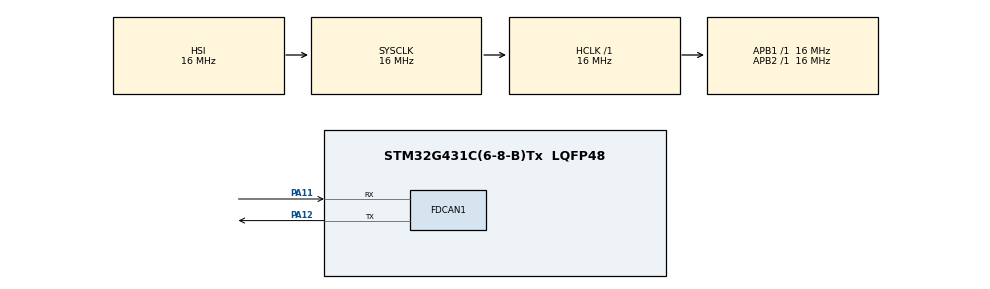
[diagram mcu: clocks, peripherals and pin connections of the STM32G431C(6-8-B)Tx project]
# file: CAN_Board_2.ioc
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FDCAN1.AutoRetransmission=DISABLE
FDCAN1.CalculateBaudRateNominal=500000
FDCAN1.CalculateTimeBitNominal=2000
FDCAN1.CalculateTimeQuantumNominal=62.5
FDCAN1.DataSyncJumpWidth=15
FDCAN1.DataTimeSeg1=16
FDCAN1.DataTimeSeg2=15
FDCAN1.FrameFormat=FDCAN_FRAME_FD_NO_BRS
FDCAN1.NominalPrescaler=1
FDCAN1.NominalSyncJumpWidth=2
FDCAN1.NominalTimeSeg1=29
Mcu.Family=STM32G4
Mcu.Name=STM32G431C(6-8-B)Tx
Mcu.Package=LQFP48
NVIC.FDCAN1_IT0_IRQn=true\:0\:0\:false\:false\:true\:true\:true\:true
NVIC.PriorityGroup=NVIC_PRIORITYGROUP_4
PA11.Mode=FDCAN_Activate
PA11.Signal=FDCAN1_RX
PA12.Mode=FDCAN_Activate
PA12.Signal=FDCAN1_TX
ProjectManager.HeapSize=0x200
ProjectManager.StackSize=0x400
ProjectManager.TargetToolchain=STM32CubeIDE
RCC.AHBFreq_Value=16000000
RCC.APB1Freq_Value=16000000
RCC.APB1TimFreq_Value=16000000
RCC.APB2Freq_Value=16000000
RCC.APB2TimFreq_Value=16000000
RCC.CortexFreq_Value=16000000
RCC.EXTERNAL_CLOCK_VALUE=12288000
RCC.HCLKFreq_Value=16000000
RCC.HSE_VALUE=8000000
RCC.HSI48_VALUE=48000000
RCC.HSI_VALUE=16000000
RCC.LSE_VALUE=32768
RCC.SYSCLKFreq_VALUE=16000000
RCC.USBFreq_Value=64000000
RCC.VCOOutputFreq_Value=128000000
VP_SYS_VS_DBSignals.Mode=DisableDeadBatterySignals
board=custom

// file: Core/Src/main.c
/* USER CODE BEGIN Header */
/**
  ******************************************************************************
  * @file           : main.c
  * @brief          : Main program body
  ******************************************************************************
  * @attention
  *
  * Copyright (c) 2025 STMicroelectronics.
  * All rights reserved.
  *
  * This software is licensed under terms that can be found in the LICENSE file
  * in the root directory of this software component.
  * If no LICENSE file comes with this software, it is provided AS-IS.
  *
  ******************************************************************************
  */
/* USER CODE END Header */
#include "main.h"

/* USER CODE BEGIN Includes */
#include <stdio.h>
#include <stdlib.h>
#include <stdint.h>
/* USER CODE END Includes */

/* USER CODE BEGIN PD */
// ID of this CAN node
#define CAN_TX_ID 0x02U
// ID expected
#define CAN_RX_ID 0x01U
/* USER CODE END PD */

FDCAN_HandleTypeDef hfdcan1;

void SystemClock_Config(void);
static void MX_GPIO_Init(void);
static void MX_FDCAN1_Init(void);

int main(void)
{

  /* MCU Configuration--------------------------------------------------------*/

  /* Reset of all peripherals, Initializes the Flash interface and the Systick. */
  HAL_Init();

  /* Configure the system clock */
  SystemClock_Config();

  /* Initialize all configured peripherals */
  MX_GPIO_Init();
  MX_FDCAN1_Init();
  /* USER CODE BEGIN 2 */
  if(HAL_FDCAN_Start(&hfdcan1) != HAL_OK) {
	  printf("error in start\n");
  }
  HAL_FDCAN_ActivateNotification(&hfdcan1, FDCAN_IT_RX_FIFO0_NEW_MESSAGE, 0);
  /* USER CODE END 2 */

  /* Infinite loop */
  while (1)
  {

  }
}

void SystemClock_Config(void)
{
  RCC_OscInitTypeDef RCC_OscInitStruct = {0};
  RCC_ClkInitTypeDef RCC_ClkInitStruct = {0};

  /** Configure the main internal regulator output voltage
  */
  HAL_PWREx_ControlVoltageScaling(PWR_REGULATOR_VOLTAGE_SCALE1);

  /** Initializes the RCC Oscillators according to the specified parameters
  * in the RCC_OscInitTypeDef structure.
  */
  RCC_OscInitStruct.OscillatorType = RCC_OSCILLATORTYPE_HSI;
  RCC_OscInitStruct.HSIState = RCC_HSI_ON;
  RCC_OscInitStruct.HSICalibrationValue = RCC_HSICALIBRATION_DEFAULT;
  RCC_OscInitStruct.PLL.PLLState = RCC_PLL_NONE;
  if (HAL_RCC_OscConfig(&RCC_OscInitStruct) != HAL_OK)
  {
    Error_Handler();
  }

  /** Initializes the CPU, AHB and APB buses clocks
  */
  RCC_ClkInitStruct.ClockType = RCC_CLOCKTYPE_HCLK|RCC_CLOCKTYPE_SYSCLK
                              |RCC_CLOCKTYPE_PCLK1|RCC_CLOCKTYPE_PCLK2;
  RCC_ClkInitStruct.SYSCLKSource = RCC_SYSCLKSOURCE_HSI;
  RCC_ClkInitStruct.AHBCLKDivider = RCC_SYSCLK_DIV1;
  RCC_ClkInitStruct.APB1CLKDivider = RCC_HCLK_DIV1;
  RCC_ClkInitStruct.APB2CLKDivider = RCC_HCLK_DIV1;

  if (HAL_RCC_ClockConfig(&RCC_ClkInitStruct, FLASH_LATENCY_0) != HAL_OK)
  {
    Error_Handler();
  }
}

static void MX_FDCAN1_Init(void)
{

  hfdcan1.Instance = FDCAN1;
  hfdcan1.Init.ClockDivider = FDCAN_CLOCK_DIV1;
  hfdcan1.Init.FrameFormat = FDCAN_FRAME_FD_NO_BRS;
  hfdcan1.Init.Mode = FDCAN_MODE_NORMAL;
  hfdcan1.Init.AutoRetransmission = DISABLE;
  hfdcan1.Init.TransmitPause = DISABLE;
  hfdcan1.Init.ProtocolException = DISABLE;
  hfdcan1.Init.NominalPrescaler = 1;
  hfdcan1.Init.NominalSyncJumpWidth = 2;
  hfdcan1.Init.NominalTimeSeg1 = 29;
  hfdcan1.Init.NominalTimeSeg2 = 2;
  hfdcan1.Init.DataPrescaler = 1;
  hfdcan1.Init.DataSyncJumpWidth = 15;
  hfdcan1.Init.DataTimeSeg1 = 16;
  hfdcan1.Init.DataTimeSeg2 = 15;
  hfdcan1.Init.StdFiltersNbr = 0;
  hfdcan1.Init.ExtFiltersNbr = 0;
  hfdcan1.Init.TxFifoQueueMode = FDCAN_TX_FIFO_OPERATION;
  if (HAL_FDCAN_Init(&hfdcan1) != HAL_OK)
  {
    Error_Handler();
  }

}

static void MX_GPIO_Init(void)
{

  /* GPIO Ports Clock Enable */
  __HAL_RCC_GPIOA_CLK_ENABLE();

}

/* USER CODE BEGIN 4 */
void HAL_FDCAN_RxFifo0Callback(FDCAN_HandleTypeDef *hfdcan, uint32_t RxFifo0ITs) {
	FDCAN_RxHeaderTypeDef RxHeader;
	uint8_t RxData;

	FDCAN_TxHeaderTypeDef TxHeader;
	uint8_t TxData = 0x05;

	// If interrupt triggered by new message
	if (RxFifo0ITs & FDCAN_IT_RX_FIFO0_NEW_MESSAGE) {
		HAL_FDCAN_GetRxMessage(hfdcan, FDCAN_RX_FIFO0, &RxHeader, &RxData);
		// check if data and ID is what we expect
		if (RxHeader.Identifier == CAN_RX_ID && RxData == 0x08) {

			TxHeader.Identifier = CAN_TX_ID;
			TxHeader.IdType = FDCAN_STANDARD_ID;
			TxHeader.TxFrameType = FDCAN_DATA_FRAME;
			TxHeader.DataLength = FDCAN_DLC_BYTES_1;
			TxHeader.ErrorStateIndicator = FDCAN_ESI_ACTIVE;
			TxHeader.BitRateSwitch = FDCAN_BRS_OFF;
			TxHeader.FDFormat = FDCAN_FD_CAN;
			TxHeader.TxEventFifoControl = FDCAN_NO_TX_EVENTS;
			TxHeader.MessageMarker = 0;

			HAL_FDCAN_AddMessageToTxFifoQ(hfdcan, &TxHeader, &TxData);
		}
		HAL_FDCAN_ActivateNotification(&hfdcan1, FDCAN_IT_RX_FIFO0_NEW_MESSAGE, 0);
	}

}
/* USER CODE END 4 */

void Error_Handler(void)
{
  __disable_irq();
  while (1)
  {
  }
}
